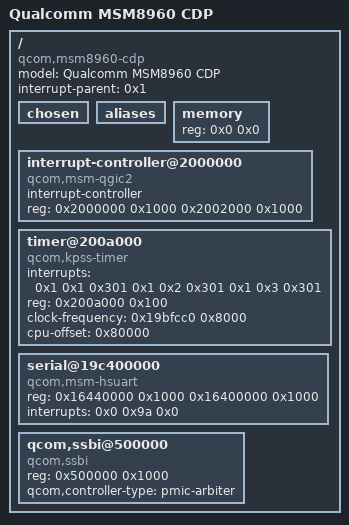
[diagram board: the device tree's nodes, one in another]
/dts-v1/;

/ {
	#address-cells = <0x1>;
	#size-cells = <0x1>;
	model = "Qualcomm MSM8960 CDP";
	compatible = "qcom,msm8960-cdp", "qcom,msm8960";
	interrupt-parent = <0x1>;

	chosen {
	};

	aliases {
	};

	memory {
		device_type = "memory";
		reg = <0x0 0x0>;
	};

	interrupt-controller@2000000 {
		compatible = "qcom,msm-qgic2";
		interrupt-controller;
		#interrupt-cells = <0x3>;
		reg = <0x2000000 0x1000 0x2002000 0x1000>;
		linux,phandle = <0x1>;
		phandle = <0x1>;
	};

	timer@200a000 {
		compatible = "qcom,kpss-timer", "qcom,msm-timer";
		interrupts = <0x1 0x1 0x301 0x1 0x2 0x301 0x1 0x3 0x301>;
		reg = <0x200a000 0x100>;
		clock-frequency = <0x19bfcc0 0x8000>;
		cpu-offset = <0x80000>;
	};

	serial@19c400000 {
		compatible = "qcom,msm-hsuart", "qcom,msm-uart";
		reg = <0x16440000 0x1000 0x16400000 0x1000>;
		interrupts = <0x0 0x9a 0x0>;
	};

	qcom,ssbi@500000 {
		compatible = "qcom,ssbi";
		reg = <0x500000 0x1000>;
		qcom,controller-type = "pmic-arbiter";
	};
};
